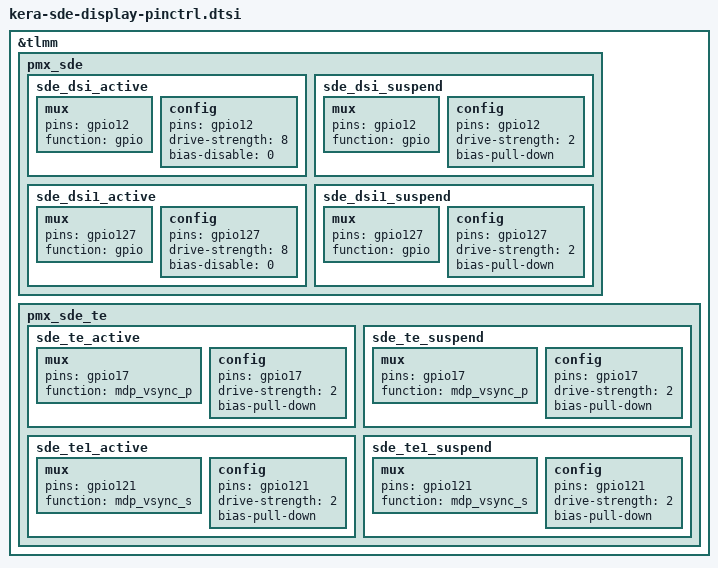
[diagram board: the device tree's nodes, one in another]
// SPDX-License-Identifier: BSD-3-Clause
/*
 * Copyright (c) 2024 Qualcomm Innovation Center, Inc. All rights reserved.
 */

&tlmm {
	pmx_sde: pmx_sde {
		sde_dsi_active: sde_dsi_active {
			mux {
				pins = "gpio12";
				function = "gpio";
			};

			config {
				pins = "gpio12";
				drive-strength = <8>;   /* 8 mA */
				bias-disable = <0>;   /* no pull */
			};
		};

		sde_dsi_suspend: sde_dsi_suspend {
			mux {
				pins = "gpio12";
				function = "gpio";
			};

			config {
				pins = "gpio12";
				drive-strength = <2>;   /* 2 mA */
				bias-pull-down;         /* PULL DOWN */
			};
		};

		sde_dsi1_active: sde_dsi1_active {
			mux {
				pins = "gpio127";
				function = "gpio";
			};

			config {
				pins = "gpio127";
				drive-strength = <8>;   /* 8 mA */
				bias-disable = <0>;   /* no pull */
			};
		};

		sde_dsi1_suspend: sde_dsi1_suspend {
			mux {
				pins = "gpio127";
				function = "gpio";
			};

			config {
				pins = "gpio127";
				drive-strength = <2>;   /* 2 mA */
				bias-pull-down;         /* PULL DOWN */
			};
		};
	};

	pmx_sde_te: pmx_sde_te {
		sde_te_active: sde_te_active {
			mux {
				pins = "gpio17";
				function = "mdp_vsync_p";
			};

			config {
				pins = "gpio17";
				drive-strength = <2>;   /* 2 mA */
				bias-pull-down;         /* PULL DOWN */
			};
		};

		sde_te_suspend: sde_te_suspend {
			mux {
				pins = "gpio17";
				function = "mdp_vsync_p";
			};

			config {
				pins = "gpio17";
				drive-strength = <2>;   /* 2 mA */
				bias-pull-down;         /* PULL DOWN */
			};
		};

		sde_te1_active: sde_te1_active {
			mux {
				pins = "gpio121";
				function = "mdp_vsync_s";
			};

			config {
				pins = "gpio121";
				drive-strength = <2>;   /* 2 mA */
				bias-pull-down;         /* PULL DOWN */
			};
		};

		sde_te1_suspend: sde_te1_suspend {
			mux {
				pins = "gpio121";
				function = "mdp_vsync_s";
			};

			config {
				pins = "gpio121";
				drive-strength = <2>;   /* 2 mA */
				bias-pull-down;         /* PULL DOWN */
			};
		};
	};
};
